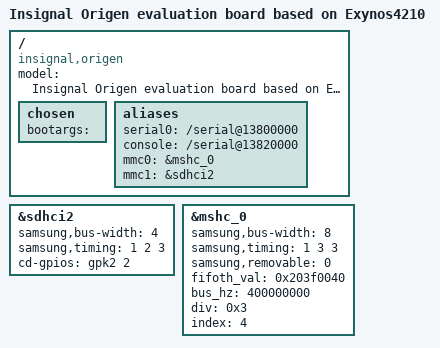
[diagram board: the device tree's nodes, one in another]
/*
 * Samsung's Exynos4210 based Origen board device tree source
 *
 * Copyright (c) 2014 Samsung Electronics Co., Ltd.
 *		http://www.samsung.com
 *
 * SPDX-License-Identifier:	GPL-2.0+
 */

/dts-v1/;
#include "skeleton.dtsi"
#include "exynos4210.dtsi"

/ {
	model = "Insignal Origen evaluation board based on Exynos4210";
	compatible = "insignal,origen", "samsung,exynos4210";

	chosen {
		bootargs ="";
	};

	aliases {
		serial0 = "/serial@13800000";
		console = "/serial@13820000";
        mmc0 = &mshc_0;
        mmc1 = &sdhci2;
	};
};

&sdhci2 {
	samsung,bus-width = <4>;
	samsung,timing = <1 2 3>;
	cd-gpios = <&gpk2 2 0>;
	status = "okay";
};
&mshc_0 {
    samsung,bus-width = <8>;
    samsung,timing = <1 3 3>;
    samsung,removable = <0>;
    fifoth_val = <0x203f0040>;
    bus_hz = <400000000>;
    div = <0x3>;
    index = <4>;
    status = "okay";
};

